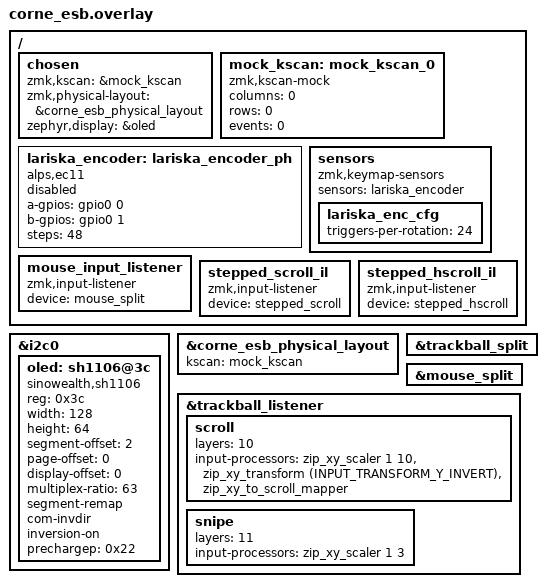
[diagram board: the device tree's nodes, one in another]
#include "corne_esb_matrix.dtsi"
#include "corne_esb_addr.dtsi"
#include "corne_esb_lariska_transform.dtsi"
#include <input/processors.dtsi>
#include <dt-bindings/zmk/input_transform.h>

/* SH1106 OLED on the dongle's i2c0. Lives in the central shield overlay (not a
 * board overlay) so it applies ONLY to the central. i2c0 pinctrl comes from the
 * board (nice_nano P0.17/P0.20). On the MDK dongle the display is turned off
 * via boards/nrf52840_mdk_dongle.conf, on the Holyiot via its board conf. */
&i2c0 {
    status = "okay";
    oled: sh1106@3c {
        compatible = "sinowealth,sh1106";
        reg = <0x3c>;
        width = <128>;
        height = <64>;
        segment-offset = <2>;
        page-offset = <0>;
        display-offset = <0>;
        multiplex-ratio = <63>;
        segment-remap;
        com-invdir;
        inversion-on;
        prechargep = <0x22>;
    };
};

/ {
    chosen {
        zmk,kscan = &mock_kscan;
        zmk,physical-layout = &corne_esb_physical_layout;
        zephyr,display = &oled;
    };

    mock_kscan: mock_kscan_0 {
        compatible = "zmk,kscan-mock";
        columns = <0>;
        rows = <0>;
        events = <0>;
    };

    /* Placeholder for the lariska QDEC encoder so the keymap's single
     * sensor-binding (&lariska_scroll, index 0) resolves on the central.
     * Real events arrive from the lariska peripheral over ESB. Uses &gpio0
     * (always defined) since the node is disabled — works on the MDK dongle
     * board too, which has no pro_micro nexus. */
    lariska_encoder: lariska_encoder_ph {
        compatible = "alps,ec11";
        a-gpios = <&gpio0 0 (GPIO_ACTIVE_HIGH | GPIO_PULL_UP)>;
        b-gpios = <&gpio0 1 (GPIO_ACTIVE_HIGH | GPIO_PULL_UP)>;
        steps = <48>;
        status = "disabled";
    };

    sensors: sensors {
        compatible = "zmk,keymap-sensors";
        sensors = <&lariska_encoder>;
        lariska_enc_cfg: lariska_enc_cfg {
            triggers-per-rotation = <24>;
        };
    };

    /* Lariska pointer motion → HID */
    mouse_input_listener: mouse_input_listener {
        compatible = "zmk,input-listener";
        status = "okay";
        device = <&mouse_split>;
    };

    /* Routes stepped_scroll events (one REL_WHEEL tick per detent) to HID. */
    stepped_scroll_il: stepped_scroll_il {
        compatible = "zmk,input-listener";
        device = <&stepped_scroll>;
    };

    /* Routes stepped_hscroll (REL_HWHEEL) events to HID. */
    stepped_hscroll_il: stepped_hscroll_il {
        compatible = "zmk,input-listener";
        device = <&stepped_hscroll>;
    };
};

&corne_esb_physical_layout {
    kscan = <&mock_kscan>;
};

&trackball_split {
    status = "okay";
};

&mouse_split {
    status = "okay";
};

/* Pointer events from the (optional) cirque right half. Same SCROL/SNIPE layer
 * processors as charybdis so the trackpad behaves consistently if used. */
&trackball_listener {
    status = "okay";

    scroll {
        layers = <10>;
        input-processors = <&zip_xy_scaler 1 10>, <&zip_xy_transform (INPUT_TRANSFORM_Y_INVERT)>, <&zip_xy_to_scroll_mapper>;
    };

    snipe {
        layers = <11>;
        input-processors = <&zip_xy_scaler 1 3>;
    };
};

/* nice_nano already defines zephyr_udc0: &usbd { status = "okay" } in its
 * base DTS, so no explicit USB enable is needed here. */
